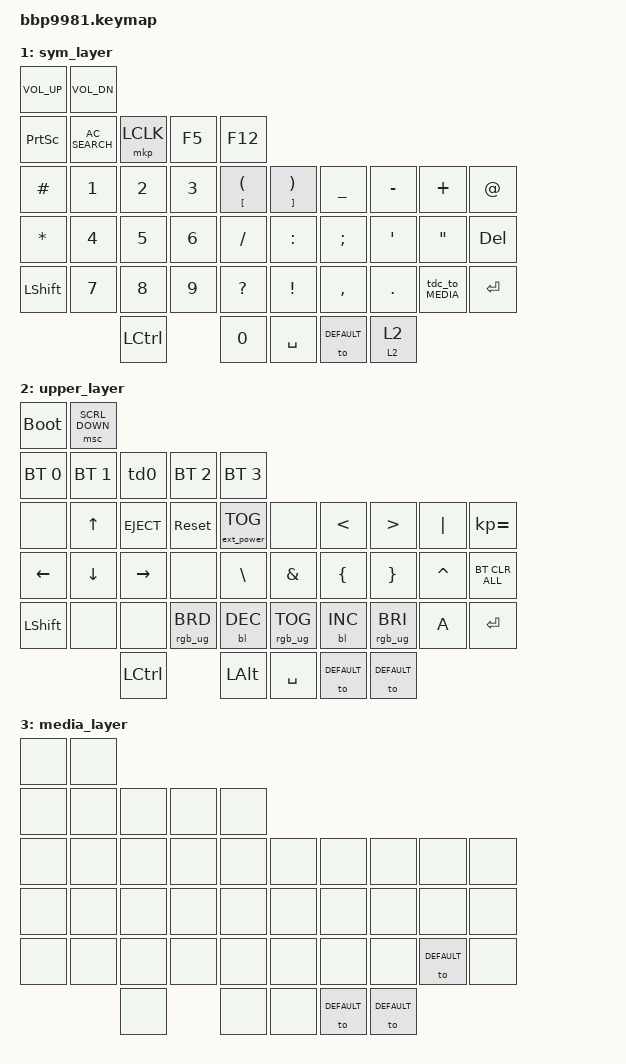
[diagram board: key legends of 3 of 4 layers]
/*
 * Copyright (c) 2025 ZitaoTech
 *
 * SPDX-License-Identifier: MIT
 */

#include <dt-bindings/zmk/mouse.h>
#include <behaviors.dtsi>
#include <dt-bindings/zmk/backlight.h>
#include <dt-bindings/zmk/bt.h>
#include <dt-bindings/zmk/ext_power.h>
#include <dt-bindings/zmk/keys.h>
#include <dt-bindings/zmk/outputs.h>
#include <dt-bindings/zmk/pointing.h>
#include <dt-bindings/zmk/rgb.h>

#define DEFAULT 0
#define SYM 1
#define UPPER 2
#define MEDIA 3

#define SL_MO(layer) &sl_mo layer layer

&sl { release-after-ms = <3000>; };

 / {
    behaviors {

        /* ===== RECENT (앱 스위처) ===== */
        app_switch: app_switch {
            compatible = "zmk,behavior-macro";
            #binding-cells = <0>;
            bindings = <
                &kp LALT
                &kp TAB
            >;
        };

        td0: tap_dance_0 {
            compatible = "zmk,behavior-tap-dance";
            #binding-cells = <0>;
            tapping-term-ms = <400>;
            bindings = <&mkp LCLK>, <&bt BT_CLR>;
        };

        td_boot_out: td_boot_out {
            compatible = "zmk,behavior-tap-dance";
            #binding-cells = <0>;
            tapping-term-ms = <400>;
            bindings = <&bootloader>, <&out OUT_TOG>;
        };

        tdc_to_SYM: td_comma_to_layer {
            compatible = "zmk,behavior-tap-dance";
            #binding-cells = <0>;
            tapping-term-ms = <400>;
            bindings = <&kp SEMI>, <&to SYM>;
        };

        tdc_to_MEDIA: td_mute_to_layer {
            compatible = "zmk,behavior-tap-dance";
            #binding-cells = <0>;
            tapping-term-ms = <400>;
            bindings = <&kp C_MUTE>, <&to MEDIA>;
        };

        hm: homerow_mods {
            compatible = "zmk,behavior-hold-tap";
            #binding-cells = <2>;
            tapping-term-ms = <400>;
            bindings = <&kp &kp>;
        };

        sl_mo: behavior_sl_mo {
            compatible = "zmk,behavior-hold-tap";
            #binding-cells = <2>;
            flavor = "hold-preferred";
            tapping-term-ms = <450>;
            bindings = <&mo &sl>;
        };

        sk_kp: behavior_sk_kp {
            compatible = "zmk,behavior-hold-tap";
            #binding-cells = <2>;
            flavor = "hold-preferred";
            tapping-term-ms = <450>;
            bindings = <&kp &sk>;
        };

        bhm: balanced_homerow_mods {
            compatible = "zmk,behavior-hold-tap";
            #binding-cells = <2>;
            flavor = "balanced";
            tapping-term-ms = <400>;
            bindings = <&kp>, <&kp>;
        };
    };

    keymap {
        compatible = "zmk,keymap";

        default_layer {
            bindings = <

/* 상단 사이드 버튼 */
&mkp RCLK      &mkp LCLK

/* 터치패드 옆 기능키 */
&kp CLCK       &app_switch    &kp BSPC     &none

/* 메인 */
&kp Q      &kp W      &kp E               &kp R           &kp T           &kp Y        &kp U  &kp I  &kp O        &kp P
&kp A      &kp S      &kp D               &kp F           &kp G           &kp H        &kp J  &kp K  &kp L        &kp BSPC
&kp LSHFT  &kp Z      &kp X               &kp C           &kp V           &kp B        &kp N  &kp M  &tdc_to_SYM  &kp ENTER

/* 하단 */
                  &sk_kp LCTRL LCTRL      &kp LALT        &kp SPACE    &mo 1  &mo 1
            >;
        };

        sym_layer {
            bindings = <
&kp C_VOL_UP  &kp C_VOL_DN
&kp PSCRN     &kp C_AC_SEARCH  &mkp LCLK  &kp F5  &kp F12
&kp HASH      &kp N1           &kp N2     &kp N3  &mt LBKT LPAR  &mt RBKT RPAR    &kp UNDER    &kp MINUS   &kp PLUS       &kp AT
&kp STAR      &kp N4           &kp N5     &kp N6  &kp SLASH      &kp COLON        &kp SEMI     &kp APOS    &kp DQT        &kp DEL
&kp LSHFT     &kp N7           &kp N8     &kp N9  &kp QMARK      &kp EXCL         &kp COMMA    &kp DOT     &tdc_to_MEDIA  &kp ENTER
                               &kp LCTRL          &kp N0         &kp SPACE        &to DEFAULT  &sl_mo 2 2
            >;
        };

        upper_layer {
            bindings = <
&bootloader   &msc SCRL_DOWN
&bt BT_SEL 0  &bt BT_SEL 1    &td0         &bt BT_SEL 2     &bt BT_SEL 3
&none         &kp UP          &kp C_EJECT  &sys_reset       &ext_power EP_TOG  &none              &kp LT       &kp GT           &kp PIPE   &kp KP_EQUAL
&kp LEFT      &kp DOWN        &kp RIGHT    &none            &kp BSLH           &kp AMPS           &kp LBRC     &kp RBRC         &kp CARET  &bt BT_CLR_ALL
&kp LSHFT     &none           &none        &rgb_ug RGB_BRD  &bl BL_DEC         &rgb_ug RGB_TOG    &bl BL_INC   &rgb_ug RGB_BRI  &kp A      &kp ENTER
                              &kp LCTRL                     &kp LALT           &kp SPACE          &to DEFAULT  &to DEFAULT
            >;
        };

        media_layer {
            bindings = <
&none  &none
&none  &none  &none  &none  &none
&none  &none  &none  &none  &none  &none    &none        &none        &none        &none
&none  &none  &none  &none  &none  &none    &none        &none        &none        &none
&none  &none  &none  &none  &none  &none    &none        &none        &to DEFAULT  &none
              &none         &none  &none    &to DEFAULT  &to DEFAULT
            >;
        };
    };
};
